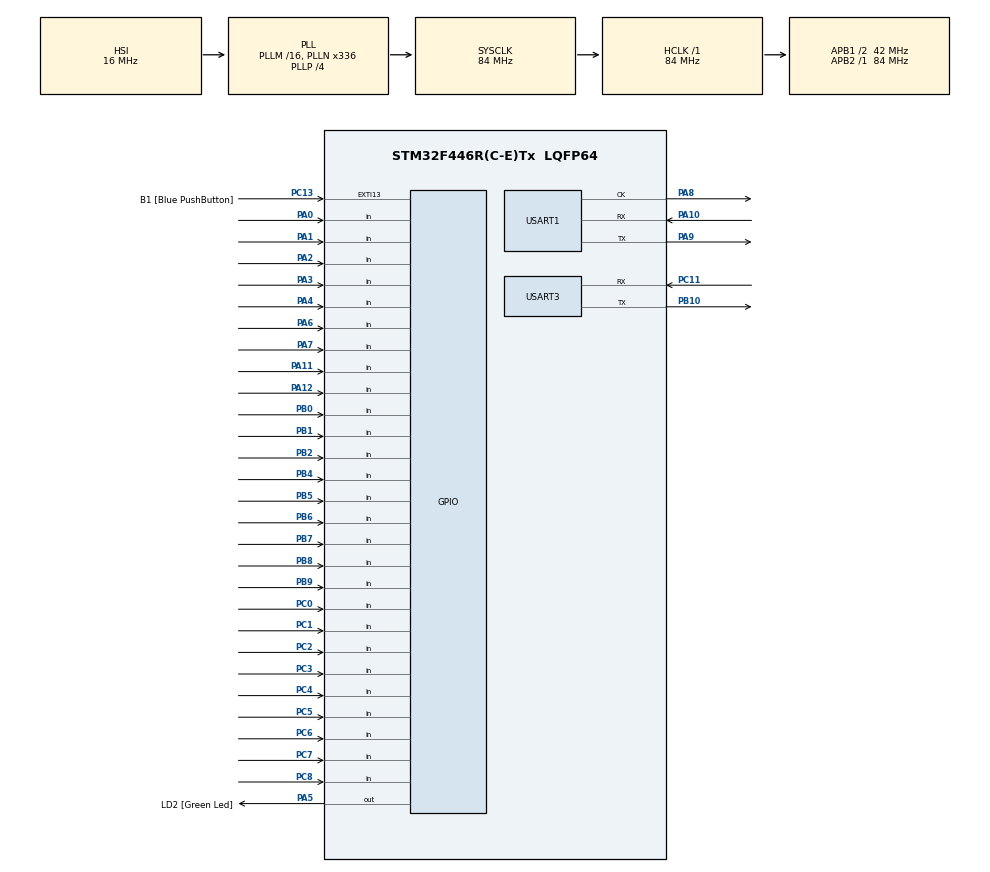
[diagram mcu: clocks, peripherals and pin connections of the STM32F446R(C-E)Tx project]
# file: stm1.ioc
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Mcu.Family=STM32F4
Mcu.Name=STM32F446R(C-E)Tx
Mcu.Package=LQFP64
NVIC.PriorityGroup=NVIC_PRIORITYGROUP_0
PA0-WKUP.Signal=GPIO_Input
PA1.Signal=GPIO_Input
PA10.Mode=Synchronous
PA10.Signal=USART1_RX
PA11.Signal=GPIO_Input
PA12.Signal=GPIO_Input
PA2.Signal=GPIO_Input
PA3.Signal=GPIO_Input
PA4.Signal=GPIO_Input
PA5.GPIO_Label=LD2 [Green Led]
PA5.Signal=GPIO_Output
PA6.Signal=GPIO_Input
PA7.Signal=GPIO_Input
PA8.Mode=Synchronous
PA8.Signal=USART1_CK
PA9.Mode=Synchronous
PA9.Signal=USART1_TX
PB0.Signal=GPIO_Input
PB1.Signal=GPIO_Input
PB10.Mode=Asynchronous
PB10.Signal=USART3_TX
PB2.Signal=GPIO_Input
PB3.GPIO_Label=SWO
PB3.Signal=SYS_JTDO-SWO
PB4.Signal=GPIO_Input
PB5.Signal=GPIO_Input
PB6.Signal=GPIO_Input
PB7.Signal=GPIO_Input
PB8.Signal=GPIO_Input
PB9.Signal=GPIO_Input
PC0.Signal=GPIO_Input
PC1.Signal=GPIO_Input
PC11.Mode=Asynchronous
PC11.Signal=USART3_RX
PC13.GPIO_Label=B1 [Blue PushButton]
PC13.GPIO_ModeDefaultEXTI=GPIO_MODE_IT_FALLING
PC13.Signal=GPXTI13
PC2.Signal=GPIO_Input
PC3.Signal=GPIO_Input
PC4.Signal=GPIO_Input
PC5.Signal=GPIO_Input
PC6.Signal=GPIO_Input
PC7.Signal=GPIO_Input
PC8.Signal=GPIO_Input
ProjectManager.HeapSize=0x200
ProjectManager.StackSize=0x400
ProjectManager.TargetToolchain=STM32CubeIDE
RCC.48MHZClocksFreq_Value=84000000
RCC.AHBFreq_Value=84000000
RCC.APB1CLKDivider=RCC_HCLK_DIV2
RCC.APB1Freq_Value=42000000
RCC.APB1TimFreq_Value=84000000
RCC.APB2Freq_Value=84000000
RCC.APB2TimFreq_Value=84000000
RCC.CortexFreq_Value=84000000
RCC.FLatency-AdvancedSettings=FLASH_LATENCY_2
RCC.HCLKFreq_Value=84000000
RCC.HSE_VALUE=8000000
RCC.HSI_VALUE=16000000
RCC.PLLN=336
RCC.PLLP=RCC_PLLP_DIV4
RCC.SYSCLKFreq_VALUE=84000000
RCC.SYSCLKSource=RCC_SYSCLKSOURCE_PLLCLK
RCC.USBFreq_Value=168000000
RCC.VCOOutputFreq_Value=336000000
USART1.VirtualMode=VM_SYNC
USART3.VirtualMode=VM_ASYNC
board=NUCLEO-F446RE

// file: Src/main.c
/* USER CODE BEGIN Header */
/**
  ******************************************************************************
  * @file           : main.c
  * @brief          : Main program body
  ******************************************************************************
  * @attention
  *
  * <h2><center>&copy; Copyright (c) 2021 STMicroelectronics.
  * All rights reserved.</center></h2>
  *
  * This software component is licensed by ST under BSD 3-Clause license,
  * the "License"; You may not use this file except in compliance with the
  * License. You may obtain a copy of the License at:
  *                        opensource.org/licenses/BSD-3-Clause
  *
  ******************************************************************************
  */

//Sory, marnowałem czas. Plan na dzisiaj 20.08 to napisać funkcje odbioru uart, wysyłania uart i odczytania pinów. Dam radę.

/* USER CODE END Header */
#include "main.h"

USART_HandleTypeDef husart1;
UART_HandleTypeDef huart3;

void SystemClock_Config(void);
static void MX_GPIO_Init(void);
static void MX_USART1_Init(void);
static void MX_USART3_UART_Init(void);

/* USER CODE BEGIN 0 */
void delay(int time)
{
    int i;
    for (i = 0; i < time * 570; i++) {}
}
/* USER CODE END 0 */

int main(void)
{

  /* MCU Configuration--------------------------------------------------------*/

  /* Reset of all peripherals, Initializes the Flash interface and the Systick. */
  HAL_Init();

  /* Configure the system clock */
  SystemClock_Config();

  /* Initialize all configured peripherals */
  MX_GPIO_Init();
  MX_USART1_Init();
  MX_USART3_UART_Init();

  /* Infinite loop */
  while (1)
  {
	  HAL_GPIO_WritePin(GPIOA, GPIO_PIN_5, GPIO_PIN_SET); // zapalenie diody
	  		delay(100);
	  		HAL_GPIO_WritePin(GPIOA, GPIO_PIN_5, GPIO_PIN_RESET); // zgaszenie diody
	  		delay(400);
  }
}

void SystemClock_Config(void)
{
  RCC_OscInitTypeDef RCC_OscInitStruct = {0};
  RCC_ClkInitTypeDef RCC_ClkInitStruct = {0};

  /** Configure the main internal regulator output voltage
  */
  __HAL_RCC_PWR_CLK_ENABLE();
  __HAL_PWR_VOLTAGESCALING_CONFIG(PWR_REGULATOR_VOLTAGE_SCALE3);
  /** Initializes the RCC Oscillators according to the specified parameters
  * in the RCC_OscInitTypeDef structure.
  */
  RCC_OscInitStruct.OscillatorType = RCC_OSCILLATORTYPE_HSI;
  RCC_OscInitStruct.HSIState = RCC_HSI_ON;
  RCC_OscInitStruct.HSICalibrationValue = RCC_HSICALIBRATION_DEFAULT;
  RCC_OscInitStruct.PLL.PLLState = RCC_PLL_ON;
  RCC_OscInitStruct.PLL.PLLSource = RCC_PLLSOURCE_HSI;
  RCC_OscInitStruct.PLL.PLLM = 16;
  RCC_OscInitStruct.PLL.PLLN = 336;
  RCC_OscInitStruct.PLL.PLLP = RCC_PLLP_DIV4;
  RCC_OscInitStruct.PLL.PLLQ = 2;
  RCC_OscInitStruct.PLL.PLLR = 2;
  if (HAL_RCC_OscConfig(&RCC_OscInitStruct) != HAL_OK)
  {
    Error_Handler();
  }
  /** Initializes the CPU, AHB and APB buses clocks
  */
  RCC_ClkInitStruct.ClockType = RCC_CLOCKTYPE_HCLK|RCC_CLOCKTYPE_SYSCLK
                              |RCC_CLOCKTYPE_PCLK1|RCC_CLOCKTYPE_PCLK2;
  RCC_ClkInitStruct.SYSCLKSource = RCC_SYSCLKSOURCE_PLLCLK;
  RCC_ClkInitStruct.AHBCLKDivider = RCC_SYSCLK_DIV1;
  RCC_ClkInitStruct.APB1CLKDivider = RCC_HCLK_DIV2;
  RCC_ClkInitStruct.APB2CLKDivider = RCC_HCLK_DIV1;

  if (HAL_RCC_ClockConfig(&RCC_ClkInitStruct, FLASH_LATENCY_2) != HAL_OK)
  {
    Error_Handler();
  }
}

static void MX_USART1_Init(void)
{

  husart1.Instance = USART1;
  husart1.Init.BaudRate = 115200;
  husart1.Init.WordLength = USART_WORDLENGTH_8B;
  husart1.Init.StopBits = USART_STOPBITS_1;
  husart1.Init.Parity = USART_PARITY_NONE;
  husart1.Init.Mode = USART_MODE_TX_RX;
  husart1.Init.CLKPolarity = USART_POLARITY_LOW;
  husart1.Init.CLKPhase = USART_PHASE_1EDGE;
  husart1.Init.CLKLastBit = USART_LASTBIT_DISABLE;
  if (HAL_USART_Init(&husart1) != HAL_OK)
  {
    Error_Handler();
  }

}

static void MX_USART3_UART_Init(void)
{

  huart3.Instance = USART3;
  huart3.Init.BaudRate = 115200;
  huart3.Init.WordLength = UART_WORDLENGTH_8B;
  huart3.Init.StopBits = UART_STOPBITS_1;
  huart3.Init.Parity = UART_PARITY_NONE;
  huart3.Init.Mode = UART_MODE_TX_RX;
  huart3.Init.HwFlowCtl = UART_HWCONTROL_NONE;
  huart3.Init.OverSampling = UART_OVERSAMPLING_16;
  if (HAL_UART_Init(&huart3) != HAL_OK)
  {
    Error_Handler();
  }

}

static void MX_GPIO_Init(void)
{
  GPIO_InitTypeDef GPIO_InitStruct = {0};

  /* GPIO Ports Clock Enable */
  __HAL_RCC_GPIOC_CLK_ENABLE();
  __HAL_RCC_GPIOA_CLK_ENABLE();
  __HAL_RCC_GPIOB_CLK_ENABLE();

  /*Configure GPIO pin Output Level */
  HAL_GPIO_WritePin(LD2_GPIO_Port, LD2_Pin, GPIO_PIN_RESET);

  /*Configure GPIO pin : B1_Pin */
  GPIO_InitStruct.Pin = B1_Pin;
  GPIO_InitStruct.Mode = GPIO_MODE_IT_FALLING;
  GPIO_InitStruct.Pull = GPIO_NOPULL;
  HAL_GPIO_Init(B1_GPIO_Port, &GPIO_InitStruct);

  /*Configure GPIO pins : PC0 PC1 PC2 PC3
                           PC4 PC5 PC6 PC7
                           PC8 */
  GPIO_InitStruct.Pin = GPIO_PIN_0|GPIO_PIN_1|GPIO_PIN_2|GPIO_PIN_3
                          |GPIO_PIN_4|GPIO_PIN_5|GPIO_PIN_6|GPIO_PIN_7
                          |GPIO_PIN_8;
  GPIO_InitStruct.Mode = GPIO_MODE_INPUT;
  GPIO_InitStruct.Pull = GPIO_NOPULL;
  HAL_GPIO_Init(GPIOC, &GPIO_InitStruct);

  /*Configure GPIO pins : PA0 PA1 PA2 PA3
                           PA4 PA6 PA7 PA11
                           PA12 */
  GPIO_InitStruct.Pin = GPIO_PIN_0|GPIO_PIN_1|GPIO_PIN_2|GPIO_PIN_3
                          |GPIO_PIN_4|GPIO_PIN_6|GPIO_PIN_7|GPIO_PIN_11
                          |GPIO_PIN_12;
  GPIO_InitStruct.Mode = GPIO_MODE_INPUT;
  GPIO_InitStruct.Pull = GPIO_NOPULL;
  HAL_GPIO_Init(GPIOA, &GPIO_InitStruct);

  /*Configure GPIO pin : LD2_Pin */
  GPIO_InitStruct.Pin = LD2_Pin;
  GPIO_InitStruct.Mode = GPIO_MODE_OUTPUT_PP;
  GPIO_InitStruct.Pull = GPIO_NOPULL;
  GPIO_InitStruct.Speed = GPIO_SPEED_FREQ_LOW;
  HAL_GPIO_Init(LD2_GPIO_Port, &GPIO_InitStruct);

  /*Configure GPIO pins : PB0 PB1 PB2 PB4
                           PB5 PB6 PB7 PB8
                           PB9 */
  GPIO_InitStruct.Pin = GPIO_PIN_0|GPIO_PIN_1|GPIO_PIN_2|GPIO_PIN_4
                          |GPIO_PIN_5|GPIO_PIN_6|GPIO_PIN_7|GPIO_PIN_8
                          |GPIO_PIN_9;
  GPIO_InitStruct.Mode = GPIO_MODE_INPUT;
  GPIO_InitStruct.Pull = GPIO_NOPULL;
  HAL_GPIO_Init(GPIOB, &GPIO_InitStruct);

}

void Error_Handler(void)
{
  __disable_irq();
  while (1)
  {
  }
}

/************************ (C) COPYRIGHT STMicroelectronics *****END OF FILE****/
